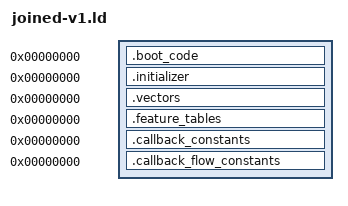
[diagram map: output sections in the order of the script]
OUTPUT_ARCH(riscv)
SECTIONS
{
 .boot_code 0 : SUBALIGN(2) { *(.boot_code)
  *(.text.tsl9_main_runtime_external_8614)
  *(.text.tsl9_runtime_callbacks_block_8638)
  *(.text.tsl9_runtime_callbacks_block_8642)
  *(.text.tsl9_runtime_callbacks_block_8646)
  *(.text.tsl9_runtime_callbacks_block_8652)
  *(.text.tsl9_runtime_callbacks_block_865e)
  *(.text.tsl9_runtime_callbacks_block_8668)
  *(.text.tsl9_runtime_callbacks_block_866c)
  *(.text.tsl9_runtime_callbacks_block_8686)
  *(.text.tsl9_runtime_callbacks_block_868e)
  *(.text.tsl9_runtime_callbacks_block_8698)
  *(.text.tsl9_runtime_callbacks_block_86a4)
  *(.text.tsl9_runtime_callbacks_block_86b8)
  *(.text.tsl9_runtime_callbacks_block_86e2)
  *(.text.tsl9_runtime_callbacks_block_86e8)
  *(.text.tsl9_runtime_callbacks_block_86fe)
  *(.text.tsl9_runtime_callbacks_block_8706)
  *(.text.tsl9_runtime_callbacks_block_871e)
  *(.text.tsl9_runtime_callbacks_block_8722)
  *(.text.tsl9_runtime_callbacks_block_873e)
  *(.text.tsl9_runtime_callbacks_block_8744)
  *(.text.tsl9_runtime_callbacks_block_8748)
  *(.text.tsl9_runtime_callbacks_block_874e)
  *(.text.tsl9_runtime_callbacks_block_875e)
  *(.text.tsl9_runtime_callbacks_block_8764)
  *(.text.tsl9_runtime_callbacks_block_8780)
  *(.text.tsl9_runtime_callbacks_block_87a4)
  *(.text.tsl9_runtime_callbacks_block_87a8)
  *(.text.tsl9_runtime_callbacks_block_87bc)
  *(.text.tsl9_runtime_callbacks_block_87c8)
  *(.text.tsl9_runtime_callbacks_block_87cc)
  *(.text.tsl9_runtime_callbacks_block_87da)
  *(.text.tsl9_runtime_callbacks_block_87f2)
  *(.text.tsl9_runtime_callbacks_block_87fa)
  *(.text.tsl9_runtime_callbacks_block_87fc)
  *(.text.tsl9_runtime_callbacks_block_8814)
  *(.text.tsl9_runtime_callbacks_block_8816)
  *(.text.tsl9_runtime_callbacks_block_882e)
  *(.text.tsl9_runtime_callbacks_block_8834)
  *(.text.tsl9_runtime_callbacks_block_8844)
  *(.text.tsl9_runtime_callbacks_block_884a)
  *(.text.tsl9_runtime_callbacks_block_8854)
  *(.text.tsl9_runtime_callbacks_block_886c)
  *(.text.tsl9_runtime_callbacks_block_8872)
  *(.text.tsl9_runtime_callbacks_block_8886)
  *(.text.tsl9_main_runtime_external_8b6e)
  *(.text.tsl9_runtime_callbacks_block_8b8a)
  *(.text.tsl9_main_runtime_external_8c82)
  *(.text.tsl9_runtime_callbacks_block_8c96)
  *(.text.tsl9_runtime_callbacks_block_8c9a)
  *(.text.tsl9_runtime_callbacks_block_8ca8)
  *(.text.tsl9_runtime_callbacks_block_8cac)
  *(.text.tsl9_runtime_callbacks_block_8cb8)
  *(.text.tsl9_runtime_callbacks_block_8cbe)
  *(.text.tsl9_runtime_callbacks_block_8d32)
  *(.text.tsl9_runtime_callbacks_block_8d3e)
  *(.text.tsl9_runtime_callbacks_block_8d4a)
  *(.text.tsl9_runtime_callbacks_block_8d56)
  *(.text.tsl9_runtime_callbacks_block_8d5c)
  *(.text.tsl9_runtime_callbacks_block_8d62)
  *(.text.tsl9_runtime_callbacks_block_8d66)
  *(.text.tsl9_runtime_callbacks_block_8d76)
  *(.text.tsl9_runtime_callbacks_block_8d7c)
  *(.text.tsl9_runtime_callbacks_block_8d82)
  *(.text.tsl9_runtime_callbacks_block_8d88)
  *(.text.tsl9_runtime_callbacks_block_8d8e)
  *(.text.tsl9_runtime_callbacks_block_8d92)
  *(.text.tsl9_runtime_callbacks_block_8da0)
  *(.text.tsl9_runtime_callbacks_block_8da6)
  *(.text.tsl9_runtime_callbacks_block_8dac)
  *(.text.tsl9_runtime_callbacks_block_8dc4)
  *(.text.tsl9_runtime_callbacks_block_8dd0)
  *(.text.tsl9_runtime_callbacks_block_8ddc)
  *(.text.tsl9_runtime_callbacks_block_8dea)
  *(.text.tsl9_runtime_callbacks_block_8df0)
  *(.text.tsl9_runtime_callbacks_block_8dfa)
  *(.text.tsl9_runtime_callbacks_block_8e06)
  *(.text.tsl9_runtime_callbacks_block_8e0e)
  *(.text.tsl9_runtime_callbacks_block_8e12)
 }
 .initializer 0 : SUBALIGN(4) { *(.initializer) }
 .vectors 0 : SUBALIGN(4) { *(.vectors) }
 .feature_tables 0 : SUBALIGN(4) { *(.feature_tables) }
 .callback_constants 0 : SUBALIGN(4) { *(.callback_constants) }
 .callback_flow_constants 0 : SUBALIGN(4) { *(.callback_flow_constants) }
 /DISCARD/ : { *(.comment) *(.riscv.attributes) *(.llvm_addrsig) }
}
